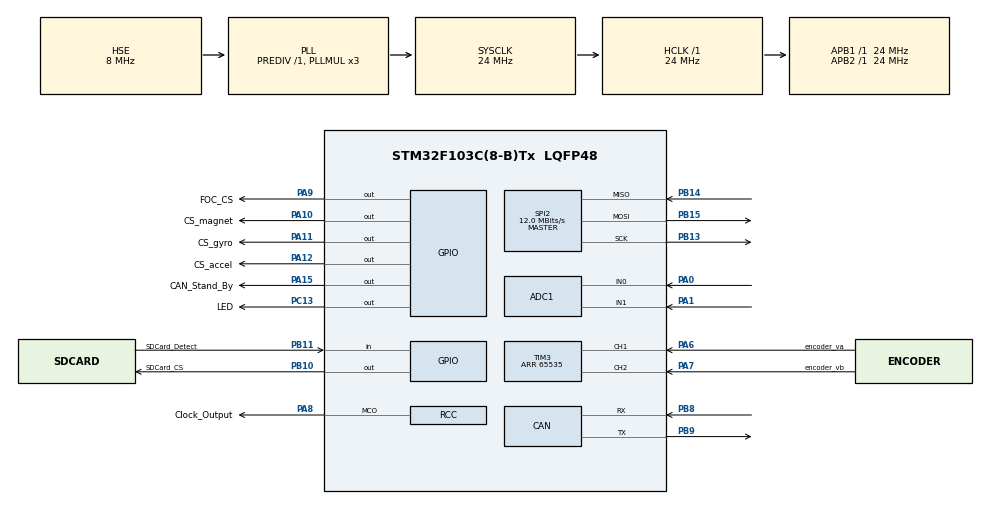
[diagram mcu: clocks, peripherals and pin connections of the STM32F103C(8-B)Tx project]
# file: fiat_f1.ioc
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ADC1.Channel-0\#ChannelRegularConversion=ADC_CHANNEL_0
ADC1.Channel-2\#ChannelRegularConversion=ADC_CHANNEL_1
ADC1.ContinuousConvMode=ENABLE
ADC1.NbrOfConversion=2
ADC1.NbrOfConversionFlag=1
ADC1.Rank-0\#ChannelRegularConversion=1
ADC1.Rank-2\#ChannelRegularConversion=2
ADC1.SamplingTime-0\#ChannelRegularConversion=ADC_SAMPLETIME_1CYCLE_5
ADC1.SamplingTime-2\#ChannelRegularConversion=ADC_SAMPLETIME_1CYCLE_5
ADC1.master=1
CAN.CalculateTimeBit=2000
CAN.CalculateTimeQuantum=666.6666666666666
FATFS._MAX_SS=512
FATFS._USE_LFN=0
Mcu.Family=STM32F1
Mcu.Name=STM32F103C(8-B)Tx
Mcu.Package=LQFP48
NVIC.PriorityGroup=NVIC_PRIORITYGROUP_4
NVIC.TIM4_IRQn=true\:0\:0\:false\:false\:true\:true\:true
PA0-WKUP.Signal=ADCx_IN0
PA1.Signal=ADCx_IN1
PA10.GPIO_Label=CS_magnet
PA10.Signal=GPIO_Output
PA11.GPIO_Label=CS_gyro
PA11.Signal=GPIO_Output
PA12.GPIO_Label=CS_accel
PA12.Signal=GPIO_Output
PA13.Mode=Trace_Asynchronous_SW
PA13.Signal=SYS_JTMS-SWDIO
PA14.Mode=Trace_Asynchronous_SW
PA14.Signal=SYS_JTCK-SWCLK
PA15.GPIO_Label=CAN_Stand_By
PA15.Signal=GPIO_Output
PA6.GPIO_Label=encoder_va
PA6.Signal=S_TIM3_CH1
PA7.GPIO_Label=encoder_vb
PA7.Signal=S_TIM3_CH2
PA8.GPIO_Label=Clock_Output
PA8.Mode=Clock-out
PA8.Signal=RCC_MCO
PA9.GPIO_Label=FOC_CS
PA9.Signal=GPIO_Output
PB10.GPIO_Label=SDCard_CS
PB10.Signal=GPIO_Output
PB11.GPIO_Label=SDCard_Detect
PB11.Signal=GPIO_Input
PB13.Mode=Full_Duplex_Master
PB13.Signal=SPI2_SCK
PB14.Mode=Full_Duplex_Master
PB14.Signal=SPI2_MISO
PB15.Mode=Full_Duplex_Master
PB15.Signal=SPI2_MOSI
PB3.Mode=Trace_Asynchronous_SW
PB3.Signal=SYS_JTDO-TRACESWO
PB8.Mode=Master
PB8.Signal=CAN_RX
PB9.Mode=Master
PB9.Signal=CAN_TX
PC13-TAMPER-RTC.GPIO_Label=LED
PC13-TAMPER-RTC.Signal=GPIO_Output
PC14-OSC32_IN.Mode=LSE-External-Oscillator
PC14-OSC32_IN.Signal=RCC_OSC32_IN
PC15-OSC32_OUT.Mode=LSE-External-Oscillator
PC15-OSC32_OUT.Signal=RCC_OSC32_OUT
PD0-OSC_IN.Mode=HSE-External-Oscillator
PD0-OSC_IN.Signal=RCC_OSC_IN
PD1-OSC_OUT.Mode=HSE-External-Oscillator
PD1-OSC_OUT.Signal=RCC_OSC_OUT
ProjectManager.HeapSize=0x200
ProjectManager.StackSize=0x400
ProjectManager.TargetToolchain=STM32CubeIDE
RCC.AHBFreq_Value=24000000
RCC.APB1Freq_Value=24000000
RCC.APB1TimFreq_Value=24000000
RCC.APB2Freq_Value=24000000
RCC.APB2TimFreq_Value=24000000
RCC.HCLKFreq_Value=24000000
RCC.PLLMUL=RCC_PLL_MUL3
RCC.PLLSourceVirtual=RCC_PLLSOURCE_HSE
RCC.RCC_MCOSource=RCC_MCO1SOURCE_PLLCLK
RCC.SYSCLKFreq_VALUE=24000000
RCC.SYSCLKSource=RCC_SYSCLKSOURCE_PLLCLK
RCC.USBFreq_Value=24000000
RTC.Date=13
RTC.Hours=3
RTC.Minutes=0
RTC.WeekDay=RTC_WEEKDAY_WEDNESDAY
SH.ADCx_IN0.0=ADC1_IN0,IN0
SH.ADCx_IN1.0=ADC1_IN1,IN1
SH.S_TIM3_CH1.0=TIM3_CH1,Encoder_Interface
SH.S_TIM3_CH2.0=TIM3_CH2,Encoder_Interface
SPI2.BaudRatePrescaler=SPI_BAUDRATEPRESCALER_2
SPI2.CalculateBaudRate=12.0 MBits/s
SPI2.Direction=SPI_DIRECTION_2LINES
SPI2.Mode=SPI_MODE_MASTER
SPI2.VirtualType=VM_MASTER
TIM3.EncoderMode=TIM_ENCODERMODE_TI12
TIM3.IC1Filter=10
TIM3.IC2Polarity=TIM_ICPOLARITY_RISING
TIM3.Period=65535
TIM4.Period=125
TIM4.Prescaler=48000
TIM4.TIM_MasterOutputTrigger=TIM_TRGO_UPDATE
VP_FATFS_VS_Generic.Mode=User_defined
VP_RTC_VS_RTC_Activate.Mode=RTC_Enabled
VP_RTC_VS_RTC_Calendar.Mode=RTC_Calendar
VP_TIM4_VS_ClockSourceINT.Mode=Internal
board=custom

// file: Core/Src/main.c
/* USER CODE BEGIN Header */
/**
  ******************************************************************************
  * @file           : main.c
  * @brief          : Main program body
  ******************************************************************************
  * @attention
  *
  * <h2><center>&copy; Copyright (c) 2019 STMicroelectronics.
  * All rights reserved.</center></h2>
  *
  * This software component is licensed by ST under BSD 3-Clause license,
  * the "License"; You may not use this file except in compliance with the
  * License. You may obtain a copy of the License at:
  *                        opensource.org/licenses/BSD-3-Clause
  *
  ******************************************************************************
  */
/* USER CODE END Header */

#include "main.h"
#include "fatfs.h"

/* USER CODE BEGIN Includes */
#include "string.h"
#include "stdio.h"
#include "fatfs_sd.h"
#include "sd_wr.h"
#include "IMU_read.h"
#include "adcUnitConversion.h"
#include "encoderMode.h"
#include "time.h"

/* USER CODE END Includes */

ADC_HandleTypeDef hadc1;

CAN_HandleTypeDef hcan;

RTC_HandleTypeDef hrtc;

SPI_HandleTypeDef hspi2;

TIM_HandleTypeDef htim3;
TIM_HandleTypeDef htim4;

/* USER CODE BEGIN PV */

uint32_t adc1 = 0;
uint32_t adc2 = 0;

//IMU
	int accel_data[3], gyro_data[3], mag_data[3];
	float acx, acy, acz, gyx, gyy, gyz;

//CAN
uint8_t ubKeyNumber = 0x0;
CAN_HandleTypeDef     CanHandle;
CAN_TxHeaderTypeDef   TxHeader;
CAN_RxHeaderTypeDef   RxHeader;
uint8_t               TxData[8];
uint8_t               RxData[8];
uint32_t              TxMailbox;

//RTC
RTC_TimeTypeDef currentTime;
RTC_DateTypeDef currentDate;

//Encoder Mode
uint32_t tick = 0;
uint32_t counter1 = 0, counter2 = 0;
float speed = 0;

/* USER CODE END PV */

void SystemClock_Config(void);
static void MX_GPIO_Init(void);
static void MX_ADC1_Init(void);
static void MX_CAN_Init(void);
static void MX_RTC_Init(void);
static void MX_SPI2_Init(void);
static void MX_TIM3_Init(void);
static void MX_TIM4_Init(void);

/* USER CODE BEGIN 0 */

FATFS fs;  // file system
FIL fil, fil2;  // file (uma por cada ficheiro a criar)
FRESULT fresult;  // to store the result
char buffer[512]; // to store data

UINT br, bw, bw2;   // file read/write count

/* capacity related variables */
//DWORD fre_clust;
DWORD total, free_space;

void HAL_TIM_PeriodElapsedCallback(TIM_HandleTypeDef *htim){

	//UNUSED(htim); será preciso?

	//counter2 = __HAL_TIM_GET_COUNTER(&htim2);
	speed = motorSpeed(&counter1, &tick, htim3);

	/* passa a fazer-se aqui?
	sprintf(str, "%f ", speed);
	update_file("encoder_data.txt", str, get_timestamp(&hrtc, &currentTime, &currentDate), stamp, &(fil[12]), &bw); */

}

/* USER CODE END 0 */

int main(void)
{

  /* MCU Configuration--------------------------------------------------------*/

  /* Reset of all peripherals, Initializes the Flash interface and the Systick. */
  HAL_Init();

  /* Configure the system clock */
  SystemClock_Config();

  /* Initialize all configured peripherals */
  MX_GPIO_Init();
  MX_ADC1_Init();
  MX_CAN_Init();
  MX_FATFS_Init();
  MX_RTC_Init();
  MX_SPI2_Init();
  MX_TIM3_Init();
  MX_TIM4_Init();
  /* USER CODE BEGIN 2 */
  printf("Hello!\n");
	  HAL_GPIO_WritePin(CS_accel_GPIO_Port, CS_accel_Pin, SET);
	  HAL_GPIO_WritePin(CS_gyro_GPIO_Port, CS_gyro_Pin, SET);
	  HAL_GPIO_WritePin(CS_magnet_GPIO_Port, CS_magnet_Pin, SET);
  fresult=mount_card (&fs);
  card_capacity(&free_space, &total);
  printf("Hello!\nFree Space: %10lu KB", free_space/2);
  //update_file("enc.txt", "OLE OLE OLE",  &fil, &bw);
  //update_file("imu_acc.txt", "IMU IMU IMU", &fil2, &bw2);

  MX_CAN_Init();
  HAL_TIM_Base_Start_IT(&htim4);

  IMU_config(&hspi2);

  char str[20];
//  float speed = 0;
  HAL_TIM_Encoder_Start(&htim3, TIM_CHANNEL_ALL);
 // HAL_TIM_Encoder_Init(&htim3, sConfig)

  counter1 = __HAL_TIM_GET_COUNTER(&htim3);
  tick = HAL_GetTick();
  /* USER CODE END 2 */

  /* Infinite loop */
  /* USER CODE BEGIN WHILE */
  while (1)
  {

	  printf("counter encoder mode: %lu \n", counter1);
	  //HAL_Delay(500);
	 /* if (HAL_GetTick() - tick > 1000L){
		  printf("hal = %lu , tick = %lu, Aquii \n", HAL_GetTick(), tick);
		  speed = motorSpeed(&counter, &tick, htim3);
	  } */

	 // speed = motorSpeed(counter, htim3);
	  printf("rpm = %f\n",speed);

	  sprintf(str , "%f ", speed);

	  printf("speed %s\n", str);
	  fresult=update_file("enc.txt", str, get_timestamp(&hrtc, &currentTime, &currentDate) , &fil, &bw);

	  HAL_GPIO_TogglePin(LED_GPIO_Port, LED_Pin);
	  //HAL_Delay(500);
	  //printf("hello\n");

	  IMU_acc_read(&hspi2, accel_data);

	  printf("\raccel data x: %d accel data y: %d accel data z: %d ", accel_data[0], accel_data[1], accel_data[2]);
	  char acxstr[20];
	  char acystr[20];
	  char aczstr[20];

	  acx = accel_data[0]*0.00098;
	  acy = accel_data[1]*0.00098;
	  acz = accel_data[2]*0.00098;
	  sprintf(acxstr, "acx - %f ", acx);
	  sprintf(acystr, "acy - %f ", acy);
	  sprintf(aczstr, "acz - %f ", acz);
	  //HAL_Delay(100);
	  update_file("imu_acc.txt", acxstr, get_timestamp(&hrtc, &currentTime, &currentDate), &fil2, &bw2);

	  update_file("imu_acc.txt", acystr, get_timestamp(&hrtc, &currentTime, &currentDate), &fil2, &bw2);

	  update_file("imu_acc.txt", aczstr, get_timestamp(&hrtc, &currentTime, &currentDate), &fil2, &bw2);

	  printf("\rreal value x: %f G real value y: %f G real value z: %f G ", acx, acy, acz);

	  IMU_gyro_read(&hspi2, gyro_data);

	  printf("\rgyro data x: %d gyro data y: %d gyro data z: %d ", gyro_data[0], gyro_data[1], gyro_data[2]);

	  gyx = (262.4/32767)*gyro_data[0];
	  gyy = (262.4/32767)*gyro_data[1];
	  gyz = (262.4/32767)*gyro_data[2];

	  printf("\rgyro real value x: %f gyro real value y: %f gyro real value z: %f  ", gyx, gyy, gyz);

	  IMU_mag_read(&hspi2, mag_data);

	  printf("\rmag data x: %d mag data y: %d mag data z: %d ", mag_data[0], mag_data[1], mag_data[2]);
	  printf("\n");

	  //testar
	  /*
	  HAL_RTC_GetTime(&hrtc, &currentTime, RTC_FORMAT_BIN);
	  HAL_RTC_GetDate(&hrtc, &currentDate, RTC_FORMAT_BIN);

	  currTime.tm_year = currentDate.Year-16;
	  currTime.tm_mday = currentDate.Date-6;
	  currTime.tm_mon  = currentDate.Month-2;

	  currTime.tm_hour = currentTime.Hours+8;
	  currTime.tm_min  = currentTime.Minutes-23;
	  currTime.tm_sec  = currentTime.Seconds;

	  timestamp = mktime(&currTime);
	  //asctime(gmtime
	  char *tim;

		tim = asctime(gmtime(&timestamp));
		*/
	  //printf("timestamp - %s \n" , get_timestamp(&hrtc, &currentTime, &currentDate));

	  /* Set the data to be transmitted */
	  // TxData[0] = 0x00;
	  //TxData[1] = 0xAD;
	  /* Start the Transmission process */
	  // if (HAL_CAN_AddTxMessage(&hcan, &TxHeader, TxData, &free_space) != HAL_OK)
	  // {
	  /* Transmission request Error */
	  // Error_Handler();
	  // }
	  // HAL_Delay(10);

	      }
    /* USER CODE END WHILE */

}

void SystemClock_Config(void)
{
  RCC_OscInitTypeDef RCC_OscInitStruct = {0};
  RCC_ClkInitTypeDef RCC_ClkInitStruct = {0};
  RCC_PeriphCLKInitTypeDef PeriphClkInit = {0};

  /** Initializes the CPU, AHB and APB busses clocks
  */
  RCC_OscInitStruct.OscillatorType = RCC_OSCILLATORTYPE_LSI|RCC_OSCILLATORTYPE_HSE;
  RCC_OscInitStruct.HSEState = RCC_HSE_ON;
  RCC_OscInitStruct.HSEPredivValue = RCC_HSE_PREDIV_DIV1;
  RCC_OscInitStruct.HSIState = RCC_HSI_ON;
  RCC_OscInitStruct.LSIState = RCC_LSI_ON;
  RCC_OscInitStruct.PLL.PLLState = RCC_PLL_ON;
  RCC_OscInitStruct.PLL.PLLSource = RCC_PLLSOURCE_HSE;
  RCC_OscInitStruct.PLL.PLLMUL = RCC_PLL_MUL3;
  if (HAL_RCC_OscConfig(&RCC_OscInitStruct) != HAL_OK)
  {
    Error_Handler();
  }
  /** Initializes the CPU, AHB and APB busses clocks
  */
  RCC_ClkInitStruct.ClockType = RCC_CLOCKTYPE_HCLK|RCC_CLOCKTYPE_SYSCLK
                              |RCC_CLOCKTYPE_PCLK1|RCC_CLOCKTYPE_PCLK2;
  RCC_ClkInitStruct.SYSCLKSource = RCC_SYSCLKSOURCE_PLLCLK;
  RCC_ClkInitStruct.AHBCLKDivider = RCC_SYSCLK_DIV1;
  RCC_ClkInitStruct.APB1CLKDivider = RCC_HCLK_DIV1;
  RCC_ClkInitStruct.APB2CLKDivider = RCC_HCLK_DIV1;

  if (HAL_RCC_ClockConfig(&RCC_ClkInitStruct, FLASH_LATENCY_0) != HAL_OK)
  {
    Error_Handler();
  }
  PeriphClkInit.PeriphClockSelection = RCC_PERIPHCLK_RTC|RCC_PERIPHCLK_ADC;
  PeriphClkInit.RTCClockSelection = RCC_RTCCLKSOURCE_LSI;
  PeriphClkInit.AdcClockSelection = RCC_ADCPCLK2_DIV2;
  if (HAL_RCCEx_PeriphCLKConfig(&PeriphClkInit) != HAL_OK)
  {
    Error_Handler();
  }
  HAL_RCC_MCOConfig(RCC_MCO, RCC_MCO1SOURCE_PLLCLK, RCC_MCODIV_1);
}

static void MX_ADC1_Init(void)
{

  ADC_ChannelConfTypeDef sConfig = {0};

  /** Common config
  */
  hadc1.Instance = ADC1;
  hadc1.Init.ScanConvMode = ADC_SCAN_ENABLE;
  hadc1.Init.ContinuousConvMode = ENABLE;
  hadc1.Init.DiscontinuousConvMode = DISABLE;
  hadc1.Init.ExternalTrigConv = ADC_SOFTWARE_START;
  hadc1.Init.DataAlign = ADC_DATAALIGN_RIGHT;
  hadc1.Init.NbrOfConversion = 2;
  if (HAL_ADC_Init(&hadc1) != HAL_OK)
  {
    Error_Handler();
  }
  /** Configure Regular Channel
  */
  sConfig.Channel = ADC_CHANNEL_0;
  sConfig.Rank = ADC_REGULAR_RANK_1;
  sConfig.SamplingTime = ADC_SAMPLETIME_1CYCLE_5;
  if (HAL_ADC_ConfigChannel(&hadc1, &sConfig) != HAL_OK)
  {
    Error_Handler();
  }
  /** Configure Regular Channel
  */
  sConfig.Channel = ADC_CHANNEL_1;
  sConfig.Rank = ADC_REGULAR_RANK_2;
  if (HAL_ADC_ConfigChannel(&hadc1, &sConfig) != HAL_OK)
  {
    Error_Handler();
  }

}

static void MX_CAN_Init(void)
{

  hcan.Instance = CAN1;
  hcan.Init.Prescaler = 16;
  hcan.Init.Mode = CAN_MODE_NORMAL;
  hcan.Init.SyncJumpWidth = CAN_SJW_1TQ;
  hcan.Init.TimeSeg1 = CAN_BS1_1TQ;
  hcan.Init.TimeSeg2 = CAN_BS2_1TQ;
  hcan.Init.TimeTriggeredMode = DISABLE;
  hcan.Init.AutoBusOff = DISABLE;
  hcan.Init.AutoWakeUp = DISABLE;
  hcan.Init.AutoRetransmission = DISABLE;
  hcan.Init.ReceiveFifoLocked = DISABLE;
  hcan.Init.TransmitFifoPriority = DISABLE;
  if (HAL_CAN_Init(&hcan) != HAL_OK)
  {
    Error_Handler();
  }

}

static void MX_RTC_Init(void)
{

  RTC_TimeTypeDef sTime = {0};
  RTC_DateTypeDef DateToUpdate = {0};

  /** Initialize RTC Only
  */
  hrtc.Instance = RTC;
  hrtc.Init.AsynchPrediv = RTC_AUTO_1_SECOND;
  hrtc.Init.OutPut = RTC_OUTPUTSOURCE_ALARM;
  if (HAL_RTC_Init(&hrtc) != HAL_OK)
  {
    Error_Handler();
  }

  /** Initialize RTC and set the Time and Date
  */
  sTime.Hours = 0x3;
  sTime.Minutes = 0x0;
  sTime.Seconds = 0x0;

  if (HAL_RTC_SetTime(&hrtc, &sTime, RTC_FORMAT_BCD) != HAL_OK)
  {
    Error_Handler();
  }
  DateToUpdate.WeekDay = RTC_WEEKDAY_WEDNESDAY;
  DateToUpdate.Month = RTC_MONTH_JANUARY;
  DateToUpdate.Date = 0x13;
  DateToUpdate.Year = 0x0;

  if (HAL_RTC_SetDate(&hrtc, &DateToUpdate, RTC_FORMAT_BCD) != HAL_OK)
  {
    Error_Handler();
  }

}

static void MX_SPI2_Init(void)
{

  /* SPI2 parameter configuration*/
  hspi2.Instance = SPI2;
  hspi2.Init.Mode = SPI_MODE_MASTER;
  hspi2.Init.Direction = SPI_DIRECTION_2LINES;
  hspi2.Init.DataSize = SPI_DATASIZE_8BIT;
  hspi2.Init.CLKPolarity = SPI_POLARITY_LOW;
  hspi2.Init.CLKPhase = SPI_PHASE_1EDGE;
  hspi2.Init.NSS = SPI_NSS_SOFT;
  hspi2.Init.BaudRatePrescaler = SPI_BAUDRATEPRESCALER_2;
  hspi2.Init.FirstBit = SPI_FIRSTBIT_MSB;
  hspi2.Init.TIMode = SPI_TIMODE_DISABLE;
  hspi2.Init.CRCCalculation = SPI_CRCCALCULATION_DISABLE;
  hspi2.Init.CRCPolynomial = 10;
  if (HAL_SPI_Init(&hspi2) != HAL_OK)
  {
    Error_Handler();
  }

}

static void MX_TIM3_Init(void)
{

  TIM_Encoder_InitTypeDef sConfig = {0};
  TIM_MasterConfigTypeDef sMasterConfig = {0};

  htim3.Instance = TIM3;
  htim3.Init.Prescaler = 0;
  htim3.Init.CounterMode = TIM_COUNTERMODE_UP;
  htim3.Init.Period = 65535;
  htim3.Init.ClockDivision = TIM_CLOCKDIVISION_DIV1;
  htim3.Init.AutoReloadPreload = TIM_AUTORELOAD_PRELOAD_DISABLE;
  sConfig.EncoderMode = TIM_ENCODERMODE_TI12;
  sConfig.IC1Polarity = TIM_ICPOLARITY_RISING;
  sConfig.IC1Selection = TIM_ICSELECTION_DIRECTTI;
  sConfig.IC1Prescaler = TIM_ICPSC_DIV1;
  sConfig.IC1Filter = 10;
  sConfig.IC2Polarity = TIM_ICPOLARITY_RISING;
  sConfig.IC2Selection = TIM_ICSELECTION_DIRECTTI;
  sConfig.IC2Prescaler = TIM_ICPSC_DIV1;
  sConfig.IC2Filter = 0;
  if (HAL_TIM_Encoder_Init(&htim3, &sConfig) != HAL_OK)
  {
    Error_Handler();
  }
  sMasterConfig.MasterOutputTrigger = TIM_TRGO_RESET;
  sMasterConfig.MasterSlaveMode = TIM_MASTERSLAVEMODE_DISABLE;
  if (HAL_TIMEx_MasterConfigSynchronization(&htim3, &sMasterConfig) != HAL_OK)
  {
    Error_Handler();
  }

}

static void MX_TIM4_Init(void)
{

  TIM_ClockConfigTypeDef sClockSourceConfig = {0};
  TIM_MasterConfigTypeDef sMasterConfig = {0};

  htim4.Instance = TIM4;
  htim4.Init.Prescaler = 48000;
  htim4.Init.CounterMode = TIM_COUNTERMODE_UP;
  htim4.Init.Period = 125;
  htim4.Init.ClockDivision = TIM_CLOCKDIVISION_DIV1;
  htim4.Init.AutoReloadPreload = TIM_AUTORELOAD_PRELOAD_DISABLE;
  if (HAL_TIM_Base_Init(&htim4) != HAL_OK)
  {
    Error_Handler();
  }
  sClockSourceConfig.ClockSource = TIM_CLOCKSOURCE_INTERNAL;
  if (HAL_TIM_ConfigClockSource(&htim4, &sClockSourceConfig) != HAL_OK)
  {
    Error_Handler();
  }
  sMasterConfig.MasterOutputTrigger = TIM_TRGO_UPDATE;
  sMasterConfig.MasterSlaveMode = TIM_MASTERSLAVEMODE_DISABLE;
  if (HAL_TIMEx_MasterConfigSynchronization(&htim4, &sMasterConfig) != HAL_OK)
  {
    Error_Handler();
  }

}

static void MX_GPIO_Init(void)
{
  GPIO_InitTypeDef GPIO_InitStruct = {0};

  /* GPIO Ports Clock Enable */
  __HAL_RCC_GPIOC_CLK_ENABLE();
  __HAL_RCC_GPIOD_CLK_ENABLE();
  __HAL_RCC_GPIOA_CLK_ENABLE();
  __HAL_RCC_GPIOB_CLK_ENABLE();

  /*Configure GPIO pin Output Level */
  HAL_GPIO_WritePin(LED_GPIO_Port, LED_Pin, GPIO_PIN_RESET);

  /*Configure GPIO pin Output Level */
  HAL_GPIO_WritePin(SDCard_CS_GPIO_Port, SDCard_CS_Pin, GPIO_PIN_RESET);

  /*Configure GPIO pin Output Level */
  HAL_GPIO_WritePin(GPIOA, FOC_CS_Pin|CS_magnet_Pin|CS_gyro_Pin|CS_accel_Pin
                          |CAN_Stand_By_Pin, GPIO_PIN_RESET);

  /*Configure GPIO pin : LED_Pin */
  GPIO_InitStruct.Pin = LED_Pin;
  GPIO_InitStruct.Mode = GPIO_MODE_OUTPUT_PP;
  GPIO_InitStruct.Pull = GPIO_NOPULL;
  GPIO_InitStruct.Speed = GPIO_SPEED_FREQ_LOW;
  HAL_GPIO_Init(LED_GPIO_Port, &GPIO_InitStruct);

  /*Configure GPIO pin : SDCard_CS_Pin */
  GPIO_InitStruct.Pin = SDCard_CS_Pin;
  GPIO_InitStruct.Mode = GPIO_MODE_OUTPUT_PP;
  GPIO_InitStruct.Pull = GPIO_NOPULL;
  GPIO_InitStruct.Speed = GPIO_SPEED_FREQ_LOW;
  HAL_GPIO_Init(SDCard_CS_GPIO_Port, &GPIO_InitStruct);

  /*Configure GPIO pin : SDCard_Detect_Pin */
  GPIO_InitStruct.Pin = SDCard_Detect_Pin;
  GPIO_InitStruct.Mode = GPIO_MODE_INPUT;
  GPIO_InitStruct.Pull = GPIO_NOPULL;
  HAL_GPIO_Init(SDCard_Detect_GPIO_Port, &GPIO_InitStruct);

  /*Configure GPIO pin : Clock_Output_Pin */
  GPIO_InitStruct.Pin = Clock_Output_Pin;
  GPIO_InitStruct.Mode = GPIO_MODE_AF_PP;
  GPIO_InitStruct.Speed = GPIO_SPEED_FREQ_LOW;
  HAL_GPIO_Init(Clock_Output_GPIO_Port, &GPIO_InitStruct);

  /*Configure GPIO pins : FOC_CS_Pin CS_magnet_Pin CS_gyro_Pin CS_accel_Pin
                           CAN_Stand_By_Pin */
  GPIO_InitStruct.Pin = FOC_CS_Pin|CS_magnet_Pin|CS_gyro_Pin|CS_accel_Pin
                          |CAN_Stand_By_Pin;
  GPIO_InitStruct.Mode = GPIO_MODE_OUTPUT_PP;
  GPIO_InitStruct.Pull = GPIO_NOPULL;
  GPIO_InitStruct.Speed = GPIO_SPEED_FREQ_LOW;
  HAL_GPIO_Init(GPIOA, &GPIO_InitStruct);

}

/* USER CODE BEGIN 4 */
int __io_putchar(int ch){
	ITM_SendChar(ch);
	return ch;
}

int _write(int file, char *ptr, int len){
	int DataIdx;

	for(DataIdx = 0; DataIdx < len; DataIdx++){
		__io_putchar(*ptr++);
	}
	return len;
}

/* USER CODE END 4 */

void Error_Handler(void)
{
}

/************************ (C) COPYRIGHT STMicroelectronics *****END OF FILE****/
